# PCM_356.0 register map
Vendor: Texas Instruments
Peripheral module from a debugger description file (folder MSP432).
Registers are 32-bit, read-write, no defined reset value unless marked. A register's access mark holds for its fields unless they carry their own. Offsets are as the file gives them; lines under a group give offsets from that group; [hi:lo] are bit positions; {n}, {i} and the like mark numbered series; 'fields as' and 'values as' point back to an identical list; <NAME> marks a mode.

## PCM
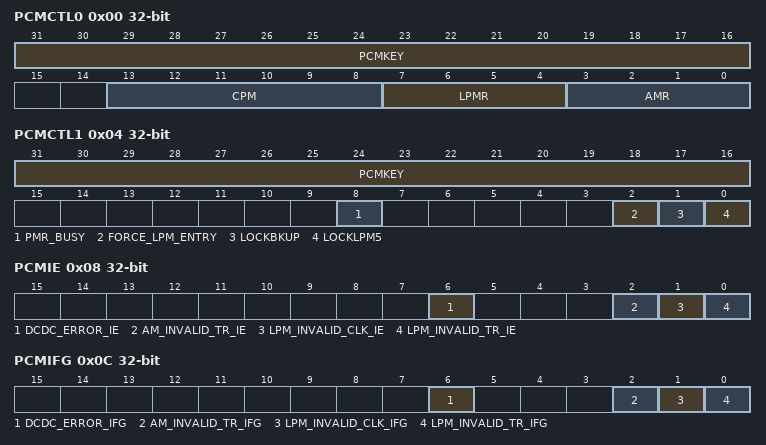
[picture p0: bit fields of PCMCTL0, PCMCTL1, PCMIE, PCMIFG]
0x00 PCMCTL0 access per field — Control 0 Register
  [31:16] PCMKEY rw
  [13:8] CPM ro — Current Power Mode
    0=AM_LDO_VCORE0 (LDO based Active Mode at Core voltage setting 0.); 1=AM_LDO_VCORE1 (LDO based Active Mode at Core voltage setting 1.); 4=AM_DCDC_VCORE0 (DC-DC based Active Mode at Core voltage setting 0.); 5=AM_DCDC_VCORE1 (DC-DC based Active Mode at Core voltage setting 1.); 8=AM_LF_VCORE0 (Low-Frequency Active Mode at Core voltage setting 0.); 9=AM_LF_VCORE1 (Low-Frequency Active Mode at Core voltage setting 1.); 16=LPM0_LDO_VCORE0 (LDO based LPM0 at Core voltage setting 0.); 17=LPM0_LDO_VCORE1 (LDO based LPM0 at Core voltage setting 1.); 20=LPM0_DCDC_VCORE0 (DC-DC based LPM0 at Core voltage setting 0.); 21=LPM0_DCDC_VCORE1 (DC-DC based LPM0 at Core voltage setting 1.); 24=LPM0_LF_VCORE0 (Low-Frequency LPM0 at Core voltage setting 0.); 25=LPM0_LF_VCORE1 (Low-Frequency LPM0 at Core voltage setting 1.); 32=LPM3
  [7:4] LPMR rw — Low Power Mode Request
    0=LPM3 (LPM3. Core voltage setting is similar to the mode from which LPM3 is entered.); 10=LPM35 (LPM3.5. Core voltage setting 0.); 12=LPM45
  [3:0] AMR rw — Active Mode Request
    0=AM_LDO_VCORE0 (LDO based Active Mode at Core voltage setting 0.); 1=AM_LDO_VCORE1 (LDO based Active Mode at Core voltage setting 1.); 4=AM_DCDC_VCORE0 (DC-DC based Active Mode at Core voltage setting 0.); 5=AM_DCDC_VCORE1 (DC-DC based Active Mode at Core voltage setting 1.); 8=AM_LF_VCORE0 (Low-Frequency Active Mode at Core voltage setting 0.); 9=AM_LF_VCORE1 (Low-Frequency Active Mode at Core voltage setting 1.)
0x04 PCMCTL1 — Control 1 Register
  [31:16] PCMKEY
  [8] PMR_BUSY — Power mode request busy flag
  [2] FORCE_LPM_ENTRY
    0=PCM aborts LPM3/LPMx.5 transition if the active clock configuration does not meet the LPM3/LPMx.5 entry criteria. PCM generates the LPM_INVALID_CLK flag on abort to LPM3/LPMx.5 entry.; 1=PCM enters LPM3/LPMx.5 after shuting off the clocks forcefully. Application needs to ensure RTC and WDT are clocked using BCLK tree to keep these modules alive in LPM3/LPM3.5. In LPM4.5 all clocks are forcefully shutoff and the core voltage is turned off.
  [1] LOCKBKUP — Lock Backup
    0=Backup domain configuration defaults to reset condition; 1=Backup domain configuration remains locked during LPM3.5 entry and exit
  [0] LOCKLPM5
    0=LPMx.5 configuration defaults to reset condition; 1=LPMx.5 configuration remains locked during LPMx.5 entry and exit
0x08 PCMIE — Interrupt Enable Register
  [all] fields
    0=DISABLE (Disabled); 1=ENABLE (Enabled)
  [6] DCDC_ERROR_IE — DC-DC error interrupt enable
  [2] AM_INVALID_TR_IE — Active mode invalid transition interrupt enable
  [1] LPM_INVALID_CLK_IE — LPM invalid clock interrupt enable
  [0] LPM_INVALID_TR_IE — LPM invalid transition interrupt enable
0x0C PCMIFG ro — Interrupt Flag Register
  [6] DCDC_ERROR_IFG — DC-DC error flag
  [2] AM_INVALID_TR_IFG — Active mode invalid transition flag
  [1] LPM_INVALID_CLK_IFG — LPM invalid clock flag
  [0] LPM_INVALID_TR_IFG — LPM invalid transition flag
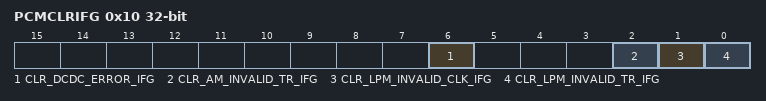
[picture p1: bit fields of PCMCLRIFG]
0x10 PCMCLRIFG — Clear Interrupt Flag Register
  [6] CLR_DCDC_ERROR_IFG — Clear DC-DC error flag
  [2] CLR_AM_INVALID_TR_IFG — Clear active mode invalid transition flag
  [1] CLR_LPM_INVALID_CLK_IFG — Clear LPM invalid clock flag
  [0] CLR_LPM_INVALID_TR_IFG — Clear LPM invalid transition flag
